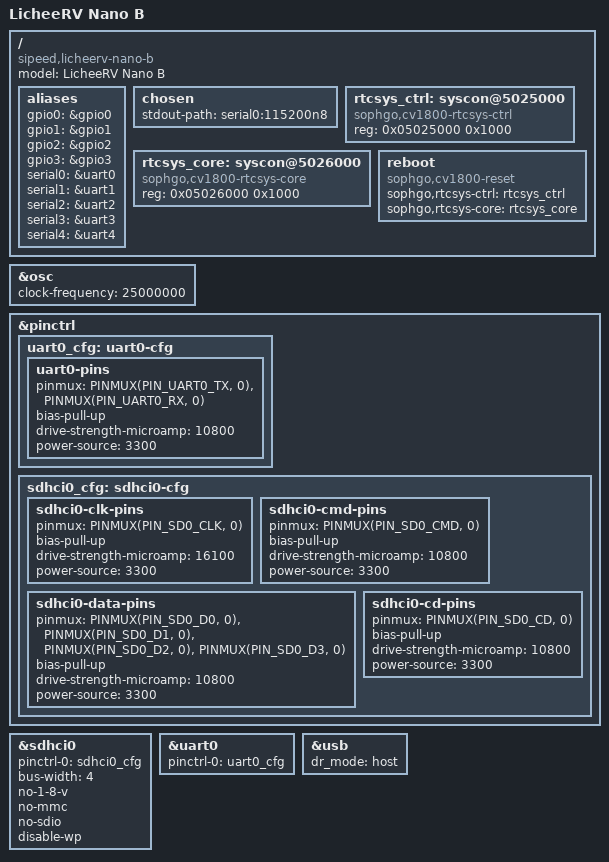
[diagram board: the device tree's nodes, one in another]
// SPDX-License-Identifier: (GPL-2.0 OR MIT)
/*
 * OpenSBI DT for the Sipeed LicheeRV Nano.
 *
 * Base SoC content comes from upstream Linux DTS sources vendored under
 * board/kernel-upstream.
 */

/dts-v1/;

#include "sg2002.dtsi"

/ {
	model = "LicheeRV Nano B";
	compatible = "sipeed,licheerv-nano-b", "sipeed,licheerv-nano", "sophgo,sg2002";

	aliases {
		gpio0 = &gpio0;
		gpio1 = &gpio1;
		gpio2 = &gpio2;
		gpio3 = &gpio3;
		serial0 = &uart0;
		serial1 = &uart1;
		serial2 = &uart2;
		serial3 = &uart3;
		serial4 = &uart4;
	};

	chosen {
		stdout-path = "serial0:115200n8";
	};

	rtcsys_ctrl: syscon@5025000 {
		compatible = "sophgo,cv1800-rtcsys-ctrl", "syscon";
		reg = <0x05025000 0x1000>;
	};

	rtcsys_core: syscon@5026000 {
		compatible = "sophgo,cv1800-rtcsys-core", "syscon";
		reg = <0x05026000 0x1000>;
	};

	reboot {
		compatible = "sophgo,cv1800-reset";
		sophgo,rtcsys-ctrl = <&rtcsys_ctrl>;
		sophgo,rtcsys-core = <&rtcsys_core>;
	};
};

&osc {
	clock-frequency = <25000000>;
};

&pinctrl {
	uart0_cfg: uart0-cfg {
		uart0-pins {
			pinmux = <PINMUX(PIN_UART0_TX, 0)>,
				 <PINMUX(PIN_UART0_RX, 0)>;
			bias-pull-up;
			drive-strength-microamp = <10800>;
			power-source = <3300>;
		};
	};

	sdhci0_cfg: sdhci0-cfg {
		sdhci0-clk-pins {
			pinmux = <PINMUX(PIN_SD0_CLK, 0)>;
			bias-pull-up;
			drive-strength-microamp = <16100>;
			power-source = <3300>;
		};

		sdhci0-cmd-pins {
			pinmux = <PINMUX(PIN_SD0_CMD, 0)>;
			bias-pull-up;
			drive-strength-microamp = <10800>;
			power-source = <3300>;
		};

		sdhci0-data-pins {
			pinmux = <PINMUX(PIN_SD0_D0, 0)>,
				 <PINMUX(PIN_SD0_D1, 0)>,
				 <PINMUX(PIN_SD0_D2, 0)>,
				 <PINMUX(PIN_SD0_D3, 0)>;
			bias-pull-up;
			drive-strength-microamp = <10800>;
			power-source = <3300>;
		};

		sdhci0-cd-pins {
			pinmux = <PINMUX(PIN_SD0_CD, 0)>;
			bias-pull-up;
			drive-strength-microamp = <10800>;
			power-source = <3300>;
		};
	};
};

&sdhci0 {
	pinctrl-0 = <&sdhci0_cfg>;
	pinctrl-names = "default";
	status = "okay";
	bus-width = <4>;
	no-1-8-v;
	no-mmc;
	no-sdio;
	disable-wp;
};

&uart0 {
	pinctrl-0 = <&uart0_cfg>;
	pinctrl-names = "default";
	status = "okay";
};

&usb {
	dr_mode = "host";
	status = "okay";
};
